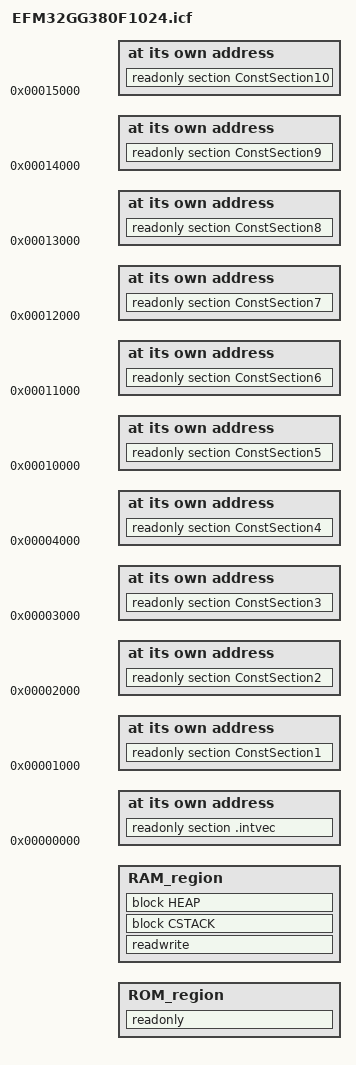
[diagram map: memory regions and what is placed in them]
/*###ICF### Section handled by ICF editor, don't touch! ****/
/*-Editor annotation file-*/
/* IcfEditorFile="$TOOLKIT_DIR$\config\ide\IcfEditor\cortex_v1_0.xml" */
/*-Specials-*/
define symbol __ICFEDIT_intvec_start__ = 0x00000000;
/*-Memory Regions-*/
define symbol __ICFEDIT_region_ROM_start__ = 0x00020000;
define symbol __ICFEDIT_region_ROM_end__   = (0x00000000+0x00100000-1);
define symbol __ICFEDIT_region_RAM_start__ = 0x20000000;
define symbol __ICFEDIT_region_RAM_end__   = (0x20000000+0x00020000-1);
/*-Sizes-*/
define symbol __ICFEDIT_size_cstack__ = 0x800;
define symbol __ICFEDIT_size_heap__   = 0x800;
/**** End of ICF editor section. ###ICF###*/

define memory mem with size = 4G;
define region ROM_region   = mem:[from __ICFEDIT_region_ROM_start__   to __ICFEDIT_region_ROM_end__];
define region RAM_region   = mem:[from __ICFEDIT_region_RAM_start__   to __ICFEDIT_region_RAM_end__];

define block CSTACK    with alignment = 8, size = __ICFEDIT_size_cstack__   { };
define block HEAP      with alignment = 8, size = __ICFEDIT_size_heap__     { };

define symbol __FIRMWARE_BOOT_STATUS_ADDR__     = 0x00001000;
define symbol __FIRMWARE_INIT_INFO_ADDR__       = 0x00002000;
define symbol __FIRMWARE_UPDATA_INFO_ADDR__     = 0x00003000;
define symbol __FIRMWARE_LOAD_INFO_ADDR__       = 0x00004000;
define symbol __ESEALBD_ID_ADDR__       	= 0x00010000;
define symbol __ESEALBD_KEY_ADDR__       	= 0x00011000;
define symbol __ESEALBD_DATA_ADDR__       	= 0x00012000;
define symbol __ESEALBD_WORK_ADDR__       	= 0x00013000;
define symbol __ESEALBD_SENSOR_ADDR__       	= 0x00014000;
define symbol __ESEALBD_STATE_ADDR__       	= 0x00015000;

initialize by copy { readwrite };
do not initialize  { section .noinit };

keep { section .intvec };
place at address mem:__ICFEDIT_intvec_start__ { readonly section .intvec };

place at address mem:__FIRMWARE_BOOT_STATUS_ADDR__     	{ readonly section ConstSection1};
place at address mem:__FIRMWARE_INIT_INFO_ADDR__       	{ readonly section ConstSection2};
place at address mem:__FIRMWARE_UPDATA_INFO_ADDR__     	{ readonly section ConstSection3};
place at address mem:__FIRMWARE_LOAD_INFO_ADDR__       	{ readonly section ConstSection4};
place at address mem:__ESEALBD_ID_ADDR__             	{ readonly section ConstSection5};
place at address mem:__ESEALBD_KEY_ADDR__             	{ readonly section ConstSection6};
place at address mem:__ESEALBD_DATA_ADDR__             	{ readonly section ConstSection7};
place at address mem:__ESEALBD_WORK_ADDR__             	{ readonly section ConstSection8};
place at address mem:__ESEALBD_SENSOR_ADDR__           	{ readonly section ConstSection9};
place at address mem:__ESEALBD_STATE_ADDR__           	{ readonly section ConstSection10};

place in ROM_region   { readonly };
place in RAM_region   { readwrite,
                        block CSTACK, 
                        block HEAP };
